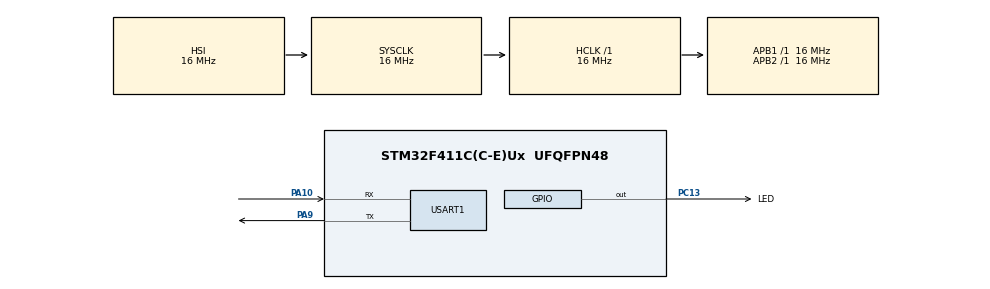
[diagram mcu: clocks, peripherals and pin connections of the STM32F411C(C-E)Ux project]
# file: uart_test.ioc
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Mcu.Family=STM32F4
PC13-ANTI_TAMP.Signal=GPIO_Output
RCC.VCOOutputFreq_Value=192000000
RCC.APB2Freq_Value=16000000
RCC.CortexFreq_Value=16000000
PA10.Mode=Asynchronous
PC13-ANTI_TAMP.GPIO_Label=LED
Mcu.Name=STM32F411C(C-E)Ux
RCC.SYSCLKFreq_VALUE=16000000
Mcu.Package=UFQFPN48
ProjectManager.StackSize=0x400
USART1.VirtualMode=VM_ASYNC
PA9.Mode=Asynchronous
PA10.Signal=USART1_RX
ProjectManager.HeapSize=0x200
ProjectManager.TargetToolchain=STM32CubeIDE
RCC.HSI_VALUE=16000000
NVIC.PriorityGroup=NVIC_PRIORITYGROUP_4
PA9.Signal=USART1_TX
RCC.APB1Freq_Value=16000000
RCC.LSE_VALUE=32768
RCC.AHBFreq_Value=16000000
RCC.HSE_VALUE=25000000
board=custom

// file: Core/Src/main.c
/* USER CODE BEGIN Header */
/**
  ******************************************************************************
  * @file           : main.c
  * @brief          : Main program body
  ******************************************************************************
  * @attention
  *
  * <h2><center>&copy; Copyright (c) 2021 STMicroelectronics.
  * All rights reserved.</center></h2>
  *
  * This software component is licensed by ST under BSD 3-Clause license,
  * the "License"; You may not use this file except in compliance with the
  * License. You may obtain a copy of the License at:
  *                        opensource.org/licenses/BSD-3-Clause
  *
  ******************************************************************************
  */
/* USER CODE END Header */
#include "main.h"

/* USER CODE BEGIN Includes */

#include <stdio.h>
#include <stdlib.h>
#include <stdint.h>

/* USER CODE END Includes */

UART_HandleTypeDef huart1;

void SystemClock_Config(void);
static void MX_GPIO_Init(void);
static void MX_USART1_UART_Init(void);

/* USER CODE BEGIN 0 */

const uint8_t SIZE = 10;

float get_random_float (float min, float max) {
	return ((float) rand() / (float) RAND_MAX) * (max - min) + min;
}

float *get_array_floats(float *arr, float start, float end) {
	uint8_t i;
	for (i = 0; i < SIZE; i++) {
		arr[i] = get_random_float(start, end);
	}
	return arr;
}

uint16_t *get_array_uint16_t(uint16_t *arr, uint16_t start, uint8_t step) {
	uint8_t i;
	for (i = 0; i < SIZE; i++) {
		arr[i] = start + step * i;
	}
	return arr;
}

/* USER CODE END 0 */

int main(void)
{

  /* MCU Configuration--------------------------------------------------------*/

  /* Reset of all peripherals, Initializes the Flash interface and the Systick. */
  HAL_Init();

  /* Configure the system clock */
  SystemClock_Config();

  /* Initialize all configured peripherals */
  MX_GPIO_Init();
  MX_USART1_UART_Init();
  /* USER CODE BEGIN 2 */

  float arry[SIZE];
  char buffer[320];

  /* USER CODE END 2 */

  /* Infinite loop */
  while (1)
  {

    /* USER CODE BEGIN 3 */

	  get_array_floats(arry, 40, 50);
	  sprintf(buffer, "%f", arry[0]);
	  HAL_UART_Transmit(&huart1, (uint8_t*)buffer, buffer, 1000);
	  HAL_UART_Transmit(&huart1, (uint8_t*)"\r\n", 2, 1000);
	  HAL_GPIO_TogglePin(GPIOC, LED_Pin);
	  HAL_Delay(500);
  }
  /* USER CODE END 3 */
}

void SystemClock_Config(void)
{
  RCC_OscInitTypeDef RCC_OscInitStruct = {0};
  RCC_ClkInitTypeDef RCC_ClkInitStruct = {0};

  /** Configure the main internal regulator output voltage
  */
  __HAL_RCC_PWR_CLK_ENABLE();
  __HAL_PWR_VOLTAGESCALING_CONFIG(PWR_REGULATOR_VOLTAGE_SCALE1);
  /** Initializes the RCC Oscillators according to the specified parameters
  * in the RCC_OscInitTypeDef structure.
  */
  RCC_OscInitStruct.OscillatorType = RCC_OSCILLATORTYPE_HSI;
  RCC_OscInitStruct.HSIState = RCC_HSI_ON;
  RCC_OscInitStruct.HSICalibrationValue = RCC_HSICALIBRATION_DEFAULT;
  RCC_OscInitStruct.PLL.PLLState = RCC_PLL_NONE;
  if (HAL_RCC_OscConfig(&RCC_OscInitStruct) != HAL_OK)
  {
    Error_Handler();
  }
  /** Initializes the CPU, AHB and APB buses clocks
  */
  RCC_ClkInitStruct.ClockType = RCC_CLOCKTYPE_HCLK|RCC_CLOCKTYPE_SYSCLK
                              |RCC_CLOCKTYPE_PCLK1|RCC_CLOCKTYPE_PCLK2;
  RCC_ClkInitStruct.SYSCLKSource = RCC_SYSCLKSOURCE_HSI;
  RCC_ClkInitStruct.AHBCLKDivider = RCC_SYSCLK_DIV1;
  RCC_ClkInitStruct.APB1CLKDivider = RCC_HCLK_DIV1;
  RCC_ClkInitStruct.APB2CLKDivider = RCC_HCLK_DIV1;

  if (HAL_RCC_ClockConfig(&RCC_ClkInitStruct, FLASH_LATENCY_0) != HAL_OK)
  {
    Error_Handler();
  }
}

static void MX_USART1_UART_Init(void)
{

  huart1.Instance = USART1;
  huart1.Init.BaudRate = 9600;
  huart1.Init.WordLength = UART_WORDLENGTH_8B;
  huart1.Init.StopBits = UART_STOPBITS_1;
  huart1.Init.Parity = UART_PARITY_NONE;
  huart1.Init.Mode = UART_MODE_TX_RX;
  huart1.Init.HwFlowCtl = UART_HWCONTROL_NONE;
  huart1.Init.OverSampling = UART_OVERSAMPLING_16;
  if (HAL_UART_Init(&huart1) != HAL_OK)
  {
    Error_Handler();
  }

}

static void MX_GPIO_Init(void)
{
  GPIO_InitTypeDef GPIO_InitStruct = {0};

  /* GPIO Ports Clock Enable */
  __HAL_RCC_GPIOC_CLK_ENABLE();
  __HAL_RCC_GPIOA_CLK_ENABLE();

  /*Configure GPIO pin Output Level */
  HAL_GPIO_WritePin(LED_GPIO_Port, LED_Pin, GPIO_PIN_RESET);

  /*Configure GPIO pin : LED_Pin */
  GPIO_InitStruct.Pin = LED_Pin;
  GPIO_InitStruct.Mode = GPIO_MODE_OUTPUT_PP;
  GPIO_InitStruct.Pull = GPIO_NOPULL;
  GPIO_InitStruct.Speed = GPIO_SPEED_FREQ_LOW;
  HAL_GPIO_Init(LED_GPIO_Port, &GPIO_InitStruct);

}

void Error_Handler(void)
{
  __disable_irq();
  while (1)
  {
  }
}

/************************ (C) COPYRIGHT STMicroelectronics *****END OF FILE****/
